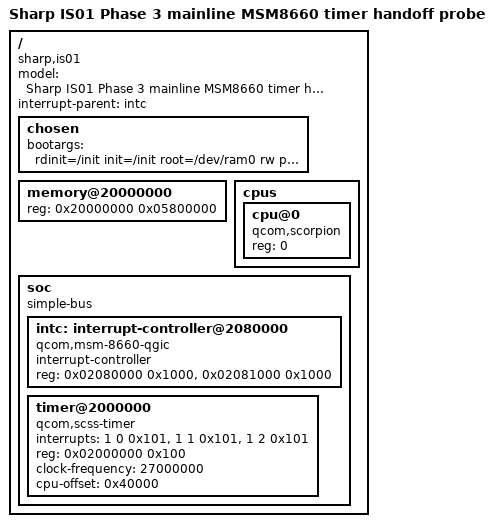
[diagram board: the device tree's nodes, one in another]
/dts-v1/;

/ {
	model = "Sharp IS01 Phase 3 mainline MSM8660 timer handoff probe";
	compatible = "sharp,is01", "qcom,msm8660", "qcom,qsd8x50";
	#address-cells = <1>;
	#size-cells = <1>;
	interrupt-parent = <&intc>;

	chosen {
		bootargs = "rdinit=/init init=/init root=/dev/ram0 rw panic=20 ignore_loglevel";
	};

	memory@20000000 {
		device_type = "memory";
		reg = <0x20000000 0x05800000>;
	};

	cpus {
		#address-cells = <1>;
		#size-cells = <0>;

		cpu@0 {
			device_type = "cpu";
			compatible = "qcom,scorpion";
			reg = <0>;
		};
	};

	soc {
		compatible = "simple-bus";
		#address-cells = <1>;
		#size-cells = <1>;
		ranges;

		intc: interrupt-controller@2080000 {
			compatible = "qcom,msm-8660-qgic";
			interrupt-controller;
			#interrupt-cells = <3>;
			reg = <0x02080000 0x1000>,
			      <0x02081000 0x1000>;
		};

		timer@2000000 {
			compatible = "qcom,scss-timer", "qcom,msm-timer";
			interrupts = <1 0 0x101>,
				     <1 1 0x101>,
				     <1 2 0x101>;
			reg = <0x02000000 0x100>;
			clock-frequency = <27000000>;
			cpu-offset = <0x40000>;
		};
	};
};
